# pmg1s3 register map
Vendor: Infineon Technologies; Series: PMG1S3; File version: 1.0
CPU: CM0PLUS r0p1, little endian, MPU, no FPU, VTOR, 2 interrupt priority bits, 32 interrupts
Registers are 32-bit, read-write, reset 0x0 unless marked. A register's access mark holds for its fields unless they carry their own. Offsets are from the block's base; [hi:lo] are bit positions; lines under a group give offsets from that group; {n}, {i} and the like mark numbered series; 'fields as' and 'values as' point back to an identical list; <NAME> marks a mode.

## USBFS — USB Device Controller
Base 0x402C0000
{0x0+4i} EP0_DR[{i}] (i=0..7) — Control End point EP0 Data Register
  [7:0] DATA_BYTE — This register is shared for both transmit and receive. The count in the EP0_CNT register determines the number of bytes received or to be transferred.
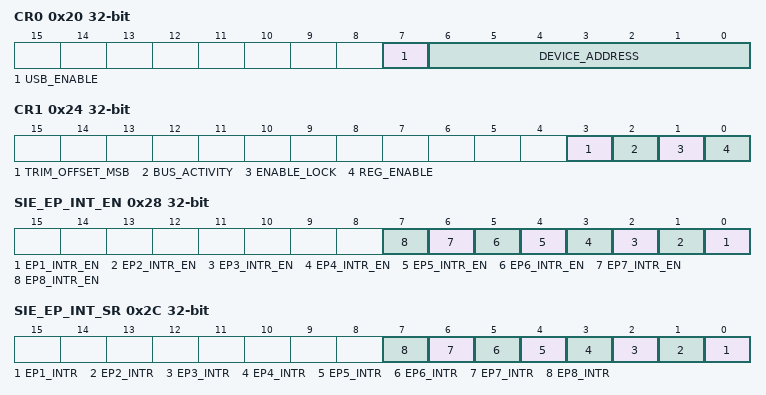
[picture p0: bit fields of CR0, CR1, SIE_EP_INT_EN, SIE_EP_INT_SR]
0x20 CR0 — USB control 0 Register
  [7] USB_ENABLE — This bit enables the device to respond to USB traffic.
  [6:0] DEVICE_ADDRESS — These bits specify the USB device address to which the SIE will respond. This address must be set by firmware and is specified by the USB Host with a SET ADDRESS command during USB enumeration. This value must be programmed by firmware when assigned during enumeration. It is not set automatically by the hardware.
0x24 CR1 — USB control 1 Register
  [3] TRIM_OFFSET_MSB — This bit enables trim bit[7].
  [2] BUS_ACTIVITY write-0-clears — The Bus Activity bit is a stickybit that detects any non-idle USB event that has occurred on the USB bus. Once set to High by the SIE to indicate the bus activity this bit retains its logical High value until firmware clears it.
  [1] ENABLE_LOCK — This bit is set to turn on the automatic frequency locking of the internal oscillator to USB traffic. Unless an external clock is being provided this bit should remain set for proper USB operation.
  [0] REG_ENABLE — This bit controls the operation of the internal USB regulator. For applications with supply voltages in the 5V range this bit is set high to enable the internal regulator. For device supply voltage in the 3.3V range this bit is cleared to connect the transceiver directly to the supply.
0x28 SIE_EP_INT_EN — USB SIE Data Endpoints Interrupt Enable Register
  [n-1] EP{n}_INTR_EN (n=1..8) — Enables interrupt for EP{n}
0x2C SIE_EP_INT_SR — USB SIE Data Endpoint Interrupt Status
  [n-1] EP{n}_INTR write-1-clears (n=1..8) — Interrupt status for EP{n}
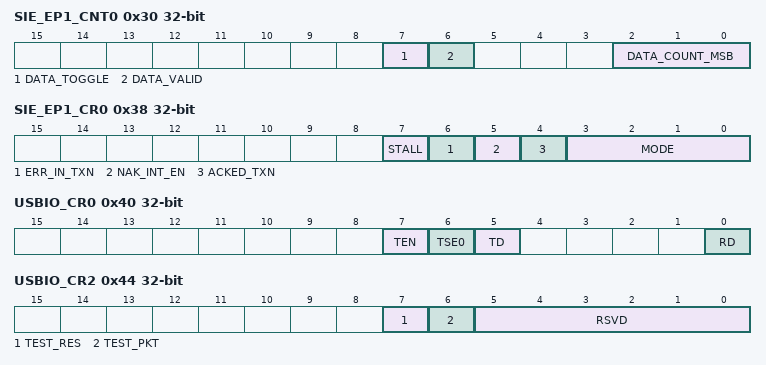
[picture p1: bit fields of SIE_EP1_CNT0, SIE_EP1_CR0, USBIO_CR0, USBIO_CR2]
0x30 SIE_EP1_CNT0 — Non-control endpoint count register
  [7] DATA_TOGGLE — This bit selects the DATA packet's toggle state. For IN transactions firmware must set this bit to the expected state. For OUT transactions the hardware sets this bit to the state of the received Data Toggle bit.
  [6] DATA_VALID write-0-clears — This bit is used for OUT transactions only and is read only. It is cleared to '0' if CRC bit stuffing errors or PID errors occur. This bit does not update for some endpoint mode settings.
    0=DATA_ERROR (No ACK'd transactions since bit was last cleared.); 1=DATA_VALID (Indicates a transaction ended with an ACK.)
  [2:0] DATA_COUNT_MSB — These bits are the 3 MSb bits of an 11-bit counter. The LSb are the Data Count[7:0] bits of the CNT1 register. Refer to the CNT1 register for more information.
0x34 SIE_EP1_CNT1 — Non-control endpoint count register
  [7:0] DATA_COUNT — These bits are the 8 LSb of a 11-bit counter. The 3 MSb bits are in the CNT0 register. The 11-bit count indicates the number of data bytes in a transaction.
0x38 SIE_EP1_CR0 — Non-control endpoint's control Register
  [7] STALL — When this bit is set the SIE stalls an OUT packet if the Mode bits are set to ACK-OUT. The SIE stalls an IN packet if the mode bits are set to ACK-IN. This bit must be clear for all other modes.
  [6] ERR_IN_TXN write-1-clears — The Error in transaction bit is set whenever an error is detected. For an IN transaction, this indicates a no response from HOST scenario. For an OUT transaction, this represents an RxErr (PID error/ CRC error/ bit-stuff error scenario). This bit is cleared by any writes to the register.
  [5] NAK_INT_EN — When set this bit causes an endpoint interrupt to be generated even when a transfer completes with a NAK.
  [4] ACKED_TXN write-1-clears — The ACK'd transaction bit is set whenever the SIE engages in a transaction to the register's endpoint that completes with an ACK packet. This bit is cleared by any writes to the register.
    0=ACKED_NO (No ACK'd transactions since bit was last cleared.); 1=ACKED_YES (Indicates a transaction ended with an ACK.)
  [3:0] MODE — The mode controls how the USB SIE responds to traffic and how the USB SIE changes the mode of that endpoint as a result of host packets to the endpoint.
    0=DISABLE (Ignore all USB traffic to this endpoint); 1=NAK_INOUT (SETUP: Accept IN: NAK OUT: NAK); 2=STATUS_OUT_ONLY (SETUP: Accept IN: STALL OUT: ACK 0B tokens, NAK others); 3=STALL_INOUT (SETUP: Accept IN: STALL OUT: STALL); 5=ISO_OUT (SETUP: Ignore IN: Ignore OUT: Accept Isochronous OUT token); 6=STATUS_IN_ONLY (SETUP: Accept IN: Respond with 0B data OUT: Stall); 7=ISO_IN (SETUP: Ignore IN: Accept Isochronous IN token OUT: Ignore); 8=NAK_OUT (SETUP: Ignore IN: Ignore OUT: NAK); 9=ACK_OUT (SETUP: Ignore IN: Ignore OUT: Accept data and ACK if STALL=0, STALL otherwise. ...); 11=ACK_OUT_STATUS_IN (SETUP: Accept IN: Respond with 0B data OUT: Accept data); 12=NAK_IN (SETUP: Ignore IN: NAK OUT: Ignore); 13=ACK_IN (SETUP: Ignore IN: Respond to IN with data if STALL=0, STALL otherwise OUT: Ignore); 15=ACK_INSTATUSOUT (SETUP: Accept IN: Respond to IN with data OUT: ACK 0B tokens, NAK others)
0x40 USBIO_CR0 (reset mask 0xE0) — USBIO Control 0 Register
  [7] TEN — USB Transmit Enable. This is used to manually transmit on the D+ and D- pins. Normally this bit should be cleared to allow the internal SIE to drive the pins. The most common reason for manually transmitting is to force a resume state on the bus.
  [6] TSE0 — Transmit Single-Ended Zero. SE0: both D+ and D- low. No effect if TEN=0.
  [5] TD — Transmit Data. Transmit a USB J or K state on the USB bus. No effect if TEN=0 or TSE0=1.
    0=DIFF_K (Force USB K state (D+ is low D- is high).); 1=DIFF_J (Force USB J state (D+ is high D- is low).)
  [0] RD ro — Received Data. This read only bit gives the state of the USB differential receiver.
    0=DIFF_LOW (D+ < D- (K state), or D+=D-=0 (SE0)); 1=DIFF_HIGH (D+ > D- (J state))
0x44 USBIO_CR2 — USBIO control 2 Register
  [7] TEST_RES — This bit is for testing the non-passthrough suspend mode pull up. When set, the resistor is applied to the D+ pin.
  [6] TEST_PKT — This bit enables the device to transmit a packet in response to an internally generated IN packet. When set, one packet will be generated.
  [5:0] RSVD ro
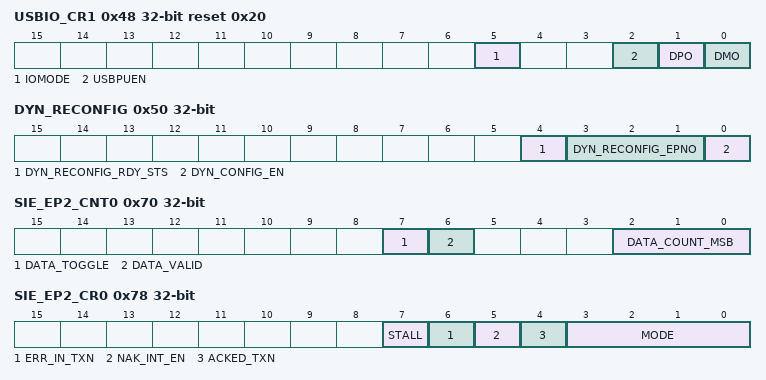
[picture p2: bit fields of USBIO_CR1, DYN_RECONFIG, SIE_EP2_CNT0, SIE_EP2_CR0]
0x48 USBIO_CR1 reset 0x20 (reset mask 0x24) — USBIO control 1 Register
  [5] IOMODE — This bit allows the D+ and D- pins to be configured for either USB mode or bit-banged modes. If this bit is set the DMI and DPI bits are used to drive the D- and D+ pins.
  [2] USBPUEN — This bit enables the connection of the internal 1.5 k pull up resistor on the D+ pin.
  [1] DPO ro — This read only bit gives the state of the D+ pin.
  [0] DMO ro — This read only bit gives the state of the D- pin.
0x50 DYN_RECONFIG — USB Dynamic reconfiguration register
  [4] DYN_RECONFIG_RDY_STS ro — This bit indicates the ready status for the dynamic reconfiguration, when set to 1, indicates the block is ready for reconfiguration.
  [3:1] DYN_RECONFIG_EPNO — These bits indicates the EP number for which reconfiguration is required when dyn_config_en bit is set to 1.
  [0] DYN_CONFIG_EN — This bit is used to enable the dynamic re-configuration for the selected EP. If set to 1, indicates the reconfiguration required for selected EP. Use 0 for EP1, 1 for EP2, etc.
0x60 SOF0 ro — Start Of Frame Register
  [7:0] FRAME_NUMBER — It has the lower 8 bits [7:0] of the SOF frame number.
0x64 SOF1 ro — Start Of Frame Register
  [2:0] FRAME_NUMBER_MSB — It has the upper 3 bits [10:8] of the SOF frame number.
0x70 SIE_EP2_CNT0 — Non-control endpoint count register
  fields as SIE_EP1_CNT0
0x74 SIE_EP2_CNT1 — Non-control endpoint count register
  fields as SIE_EP1_CNT1
0x78 SIE_EP2_CR0 — Non-control endpoint's control Register
  fields as SIE_EP1_CR0
0x80 OSCLK_DR0 ro reset not defined — Oscillator lock data register 0
  [7:0] ADDER — These bits return the lower 8 bits of the oscillator locking circuits adder output.
0x84 OSCLK_DR1 ro reset not defined — Oscillator lock data register 1
  [6:0] ADDER_MSB — These bits return the upper 7 bits of the oscillator locking circuits adder output.
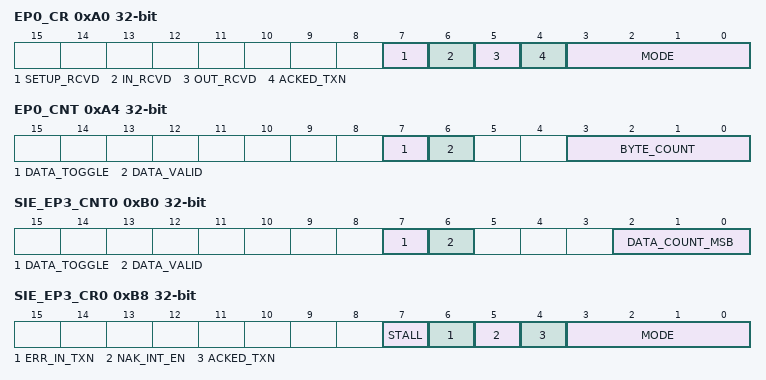
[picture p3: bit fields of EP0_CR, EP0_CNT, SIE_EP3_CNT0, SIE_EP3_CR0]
0xA0 EP0_CR — Endpoint0 control Register
  [7] SETUP_RCVD write-1-clears — When set this bit indicates a valid SETUP packet was received and ACKed. This bit is forced HIGH from the start of the data packet phase of the SETUP transaction until the start of the ACK packet returned by the SIE. The CPU is prevented from clearing this bit during this interval. After this interval the bit will remain set until cleared by firmware. While this bit is set to '1' the CPU cannot write to the EP0_DRx registers. This prevents firmware from overwriting an incoming SETUP transaction before firmware has a chance to read the SETUP data. This bit is cleared by any non-locked writes to the register.
  [6] IN_RCVD write-1-clears — When set this bit indicates a valid IN packet has been received. This bit is updated to '1' after the host acknowledges an IN data packet. When clear this bit indicates either no IN has been received or that the host did not acknowledge the IN data by sending ACK handshake. It is cleared by any writes to the register.
  [5] OUT_RCVD write-1-clears — When set this bit indicates a valid OUT packet has been received and ACKed. This bit is updated to '1' after the last received packet in an OUT transaction. When clear this bit indicates no OUT received. It is cleared by any writes to the register.
  [4] ACKED_TXN write-1-clears — The ACK'd transaction bit is set whenever the SIE engages in a transaction to the register's endpoint that completes with an ACK packet. This bit is cleared by any writes to the register.
    values as SIE_EP1_CR0.ACKED_TXN
  [3:0] MODE — The mode controls how the USB SIE responds to traffic and how the USB SIE changes the mode of that endpoint as a result of host packets to the endpoint.
    values as SIE_EP1_CR0.MODE
0xA4 EP0_CNT — Endpoint0 count Register
  [7] DATA_TOGGLE — This bit selects the DATA packet's toggle state. For IN transactions firmware must set this bit to the expected state. For OUT transactions the hardware sets this bit to the state of the received Data Toggle bit.
  [6] DATA_VALID write-0-clears — This bit is used for OUT/SETUP transactions only and is read only. It is cleared to '0' if CRC bit stuffing errors or PID errors occur. This bit does not update for some endpoint mode settings.
    values as SIE_EP1_CNT0.DATA_VALID
  [3:0] BYTE_COUNT — These bits indicate the number of data bytes in a transaction. For IN transactions firmware loads the count with the number of bytes to be transmitted to the host from the endpoint FIFO. Valid values are 0 to 8. For OUT or SETUP transactions the count is updated by hardware to the number of data bytes received plus two for the CRC bytes. Valid values are 2 to 10.
0xB0 SIE_EP3_CNT0 — Non-control endpoint count register
  fields as SIE_EP1_CNT0
0xB4 SIE_EP3_CNT1 — Non-control endpoint count register
  fields as SIE_EP1_CNT1
0xB8 SIE_EP3_CR0 — Non-control endpoint's control Register
  fields as SIE_EP1_CR0
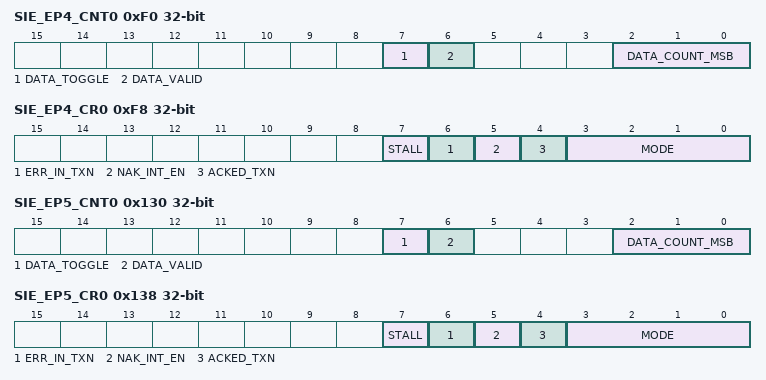
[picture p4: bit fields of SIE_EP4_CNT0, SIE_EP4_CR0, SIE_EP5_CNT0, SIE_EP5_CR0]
0xF0 SIE_EP4_CNT0 — Non-control endpoint count register
  fields as SIE_EP1_CNT0
0xF4 SIE_EP4_CNT1 — Non-control endpoint count register
  fields as SIE_EP1_CNT1
0xF8 SIE_EP4_CR0 — Non-control endpoint's control Register
  fields as SIE_EP1_CR0
0x130 SIE_EP5_CNT0 — Non-control endpoint count register
  fields as SIE_EP1_CNT0
0x134 SIE_EP5_CNT1 — Non-control endpoint count register
  fields as SIE_EP1_CNT1
0x138 SIE_EP5_CR0 — Non-control endpoint's control Register
  fields as SIE_EP1_CR0
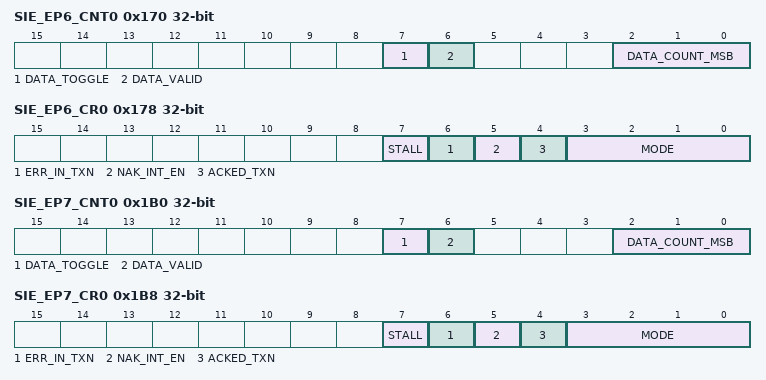
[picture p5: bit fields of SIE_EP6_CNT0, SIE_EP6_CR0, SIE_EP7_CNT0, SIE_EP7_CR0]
0x170 SIE_EP6_CNT0 — Non-control endpoint count register
  fields as SIE_EP1_CNT0
0x174 SIE_EP6_CNT1 — Non-control endpoint count register
  fields as SIE_EP1_CNT1
0x178 SIE_EP6_CR0 — Non-control endpoint's control Register
  fields as SIE_EP1_CR0
0x1B0 SIE_EP7_CNT0 — Non-control endpoint count register
  fields as SIE_EP1_CNT0
0x1B4 SIE_EP7_CNT1 — Non-control endpoint count register
  fields as SIE_EP1_CNT1
0x1B8 SIE_EP7_CR0 — Non-control endpoint's control Register
  fields as SIE_EP1_CR0
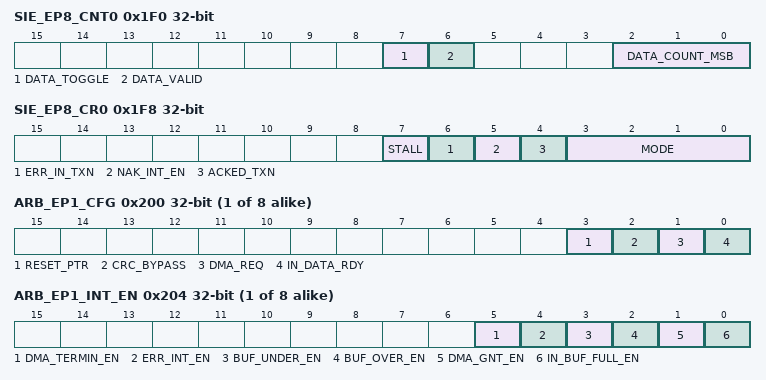
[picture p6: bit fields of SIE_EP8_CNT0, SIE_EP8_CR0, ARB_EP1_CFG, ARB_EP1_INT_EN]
0x1F0 SIE_EP8_CNT0 — Non-control endpoint count register
  fields as SIE_EP1_CNT0
0x1F4 SIE_EP8_CNT1 — Non-control endpoint count register
  fields as SIE_EP1_CNT1
0x1F8 SIE_EP8_CR0 — Non-control endpoint's control Register
  fields as SIE_EP1_CR0
{0x1C0+0x40*i} ARB_EP{i}_CFG (i=1..8) — Endpoint Configuration Register
  [3] RESET_PTR — Configuration Setting to Reset the RA and WA Pointers to their start values at the End of Packet transaction.
    0=RESET_KRYPTON (Do not Reset Pointer; Krypton Backward compatibility mode); 1=RESET_NORMAL (Reset Pointer; recommended value for reduction of CPU Configuration Writes.)
  [2] CRC_BYPASS — Configuration Setting to prevent CRC bytes from being written to memory and being read by firmware
    0=CRC_NORMAL (No CRC bypass; CRC bytes will be written to memory and Termin will be generated for the CRC byte/s); 1=CRC_BYPASS (CRC Bypass Set; CRC bytes will not be written into memory and Termin will be generated for the last data byte/s)
  [1] DMA_REQ — Manual DMA Request for a particular (1 to 8) endpoint; changing this field from 0 to 1 causes a DMA request to be generated.
  [0] IN_DATA_RDY — Indication that Endpoint Packet Data is Ready in Main memory
{0x1C4+0x40*i} ARB_EP{i}_INT_EN (i=1..8) — Endpoint Interrupt Enable Register
  [5] DMA_TERMIN_EN — Endpoint DMA Terminated Enable
  [4] ERR_INT_EN — Endpoint Error in Transaction Interrupt Enable
  [3] BUF_UNDER_EN — Endpoint Buffer Underflow Enable
  [2] BUF_OVER_EN — Endpoint Buffer Overflow Enable
  [1] DMA_GNT_EN — Endpoint DMA Grant Enable
  [0] IN_BUF_FULL_EN — IN Endpoint Local Buffer Full Enable
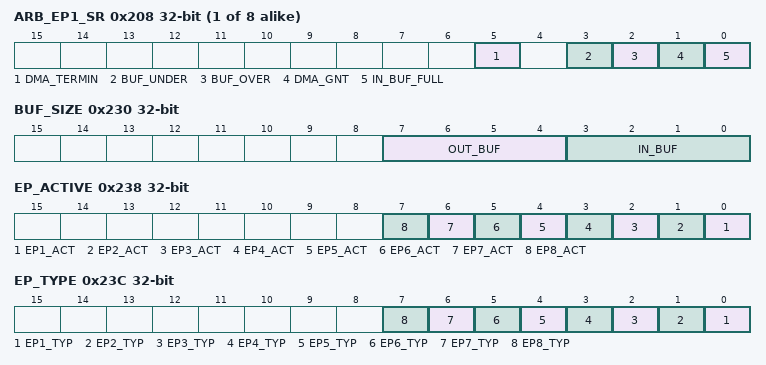
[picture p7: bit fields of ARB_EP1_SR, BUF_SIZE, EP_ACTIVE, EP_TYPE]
{0x1C8+0x40*i} ARB_EP{i}_SR (i=1..8) — Endpoint Interrupt Enable Register
  [5] DMA_TERMIN write-1-clears — Endpoint DMA Terminated Interrupt
  [3] BUF_UNDER write-1-clears — Endpoint Buffer Underflow Interrupt
  [2] BUF_OVER write-1-clears — Endpoint Buffer Overflow Interrupt
  [1] DMA_GNT write-1-clears — Endpoint DMA Grant Interrupt
  [0] IN_BUF_FULL write-1-clears — IN Endpoint Local Buffer Full Interrupt
{0x1D0+0x40*i} ARB_RW{i}_WA (i=1..8) — Endpoint Write Address value
  [7:0] WA — Write Address for EP
{0x1D4+0x40*i} ARB_RW{i}_WA_MSB (i=1..8) — Endpoint Write Address value
  [0] WA_MSB — Write Address for EP
{0x1D8+0x40*i} ARB_RW{i}_RA (i=1..8) — Endpoint Read Address value
  [7:0] RA — Read Address for EP
{0x1DC+0x40*i} ARB_RW{i}_RA_MSB (i=1..8) — Endpoint Read Address value
  [0] RA_MSB — Read Address for EP
{0x1E0+0x40*i} ARB_RW{i}_DR reset not defined (i=1..8) — Endpoint Data Register
  [7:0] DR — Data Register for EP ; This register is linked to the memory, hence reset value is undefined
0x230 BUF_SIZE — Dedicated Endpoint Buffer Size Register
  [7:4] OUT_BUF — Buffer size for OUT Endpoints.
  [3:0] IN_BUF — Buffer size for IN Endpoints.
0x238 EP_ACTIVE — Endpoint Active Indication Register
  [n-1] EP{n}_ACT (n=1..8) — Indicates that Endpoint is currently active.
0x23C EP_TYPE — Endpoint Type (IN/OUT) Indication
  [all] fields
    0=EP_IN (IN outpoint); 1=EP_OUT (OUT outpoint)
  [n-1] EP{n}_TYP (n=1..8) — Endpoint Type Indication.
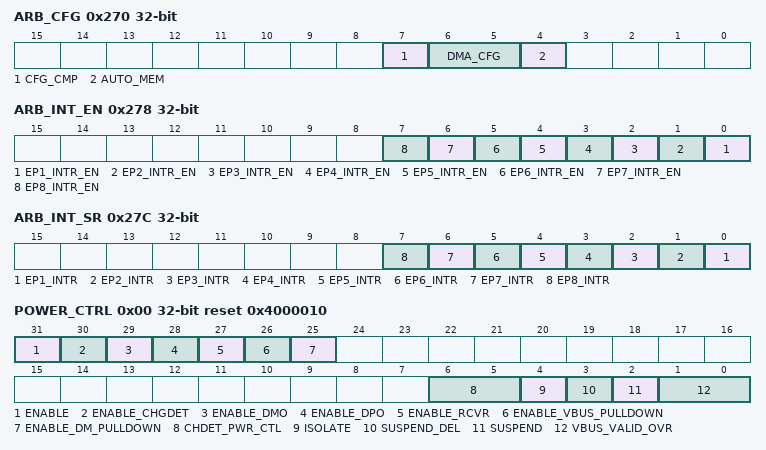
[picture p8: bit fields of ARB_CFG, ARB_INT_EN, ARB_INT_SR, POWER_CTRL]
0x270 ARB_CFG — Arbiter Configuration Register
  [7] CFG_CMP — Register Configuration Complete Indication. Posedge is detected on this bit. Hence a 0 to 1 transition is required.
  [6:5] DMA_CFG — DMA Access Configuration.
    0=DMA_NONE (No DMA); 1=DMA_MANUAL (Manual DMA); 2=DMA_AUTO (Auto DMA)
  [4] AUTO_MEM — Enables Auto Memory Configuration. Manual memory configuration by default.
0x274 USB_CLK_EN — USB Block Clock Enable Register
  [0] CSR_CLK_EN — Clock Enable for Core Logic clocked by AHB bus clock
0x278 ARB_INT_EN — Arbiter Interrupt Enable
  [n-1] EP{n}_INTR_EN (n=1..8) — Enables interrupt for EP{n}
0x27C ARB_INT_SR ro — Arbiter Interrupt Status
  [n-1] EP{n}_INTR (n=1..8) — Interrupt status for EP{n}
0x2B0 CWA — Common Area Write Address
  [7:0] CWA — Write Address for Common Area
0x2B4 CWA_MSB — Endpoint Read Address value
  [0] CWA_MSB — Write Address for Common Area
0x2F0 DMA_THRES — DMA Burst / Threshold Configuration
  [7:0] DMA_THS — DMA Threshold count
0x2F4 DMA_THRES_MSB — DMA Burst / Threshold Configuration
  [0] DMA_THS_MSB — DMA Threshold count
0x330 BUS_RST_CNT reset 0xA — Bus Reset Count Register
  [3:0] BUS_RST_CNT — Bus Reset Count Length
{0x400+4i} MEM_DATA[{i}] (i=0..511) reset not defined — DATA
  fields as ARB_RW1_DR
0x1060 SOF16 ro — Start Of Frame Register
  [10:0] FRAME_NUMBER16 — The frame number (11b)
0x1080 OSCLK_DR16 ro reset not defined — Oscillator lock data register
  [14:0] ADDER16 — These bits return the oscillator locking circuits adder output.
{0x11D0+0x40*i} ARB_RW{i}_WA16 (i=1..8) — Endpoint Write Address value
  [8:0] WA16 — Write Address for EP
{0x11D8+0x40*i} ARB_RW{i}_RA16 (i=1..8) — Endpoint Read Address value
  [8:0] RA16 — Read Address for EP
{0x11E0+0x40*i} ARB_RW{i}_DR16 reset not defined (i=1..8) — Endpoint Data Register
  [15:0] DR16 — Data Register for EP ; This register is linked to the memory, hence reset value is undefined
0x12B0 CWA16 — Common Area Write Address
  [8:0] CWA16 — Write Address for Common Area
0x12F0 DMA_THRES16 — DMA Burst / Threshold Configuration
  [8:0] DMA_THS16 — DMA Threshold count
0x2000 BCD group — USB Device Controller Battery Charger Detect
  0x00 POWER_CTRL reset 0x4000010 — Power Control Register
    [31] ENABLE — Mast enable of PHY and Charger Detector. Nothing will work until this bit is set.
    [30] ENABLE_CHGDET — Enables the charger detection circuitry. After USB has connected, this circuitry can be disabled to save power.
    [29] ENABLE_DMO — Enables the signle ended receiver on D-.
    [28] ENABLE_DPO — Enables the single ended receiver on D+.
    [27] ENABLE_RCVR — Enables the differential USB receiver.
    [26] ENABLE_VBUS_PULLDOWN — Enables the weak pull down on the VBUS, default on, to prevent floating node crow bar currents.
    [25] ENABLE_DM_PULLDOWN — Enables the ~15k pull down on the DM, default off. The 15k pull down is needed for Data Contact Detection (DCD).
    [6:5] CHDET_PWR_CTL — Power programmability for bandgap voltage buffer in the charger detect block. See s8bg_vrefbuf public cell for more information. Default '0' is low power mode.
    [4] ISOLATE — Isolates the PHY outputs. Clear this bit at least 2us after vbus is known to be valid (vbus_valid=1). Isolation will be forced when vbus_valid goes low (see VBUS_VALID_OVR).
    [3] SUSPEND_DEL — Delayed version of SUSPEND. Always set SUSPEND and SUSPEND_DEL together in a single register write. When taking PHY out of suspend mode, first clear SUSPEND, then clear SUSPEND_DEL at least 2us later.
    [2] SUSPEND — Put PHY into Suspend mode. If the PHY is enabled, this bit MUST be set before entering a low power mode (DeepSleep/Hibernate).
    [1:0] VBUS_VALID_OVR — Overrides the value received from the GPIO input buffer connected to VBUS: 0: Force vbus_valid=0 1: Force vbus_valid=1 2: Use vbus_valid signal from GPIO input 3: Use vbus_valid signal from PHY detector
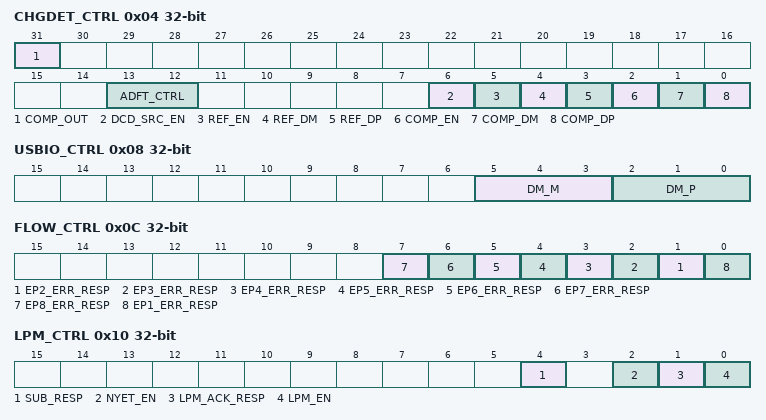
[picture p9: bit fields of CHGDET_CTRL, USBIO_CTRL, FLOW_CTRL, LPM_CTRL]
  0x04 CHGDET_CTRL (reset mask 0x307F) — Charger Detection Control Register
    [31] COMP_OUT ro — Output of the primary/secondary detection comparator. This output is not filtered or debounced and must be polled in software.
    [13:12] ADFT_CTRL — ADFT option to bring out buffered version of voltage reference input or adft intput to ADFT output (adft_out).
      0=ADFT_NORMAL (Normal operating mode, reference buffer used to generate internal references. adft_out pulled low.); 1=ADFT_VBG (Use reference buffer to bring out voltage reference input (vbg) onto adft_out.); 2=ADFT_DONTUSE (Illegal - do not use.); 3=ADFT_ADFTIN (Use reference buffer to bring out buffered version of system level adft input (adft_in) onto adft_out.)
    [6] DCD_SRC_EN — Enable the Data Contact Detect current source on D+
    [5] REF_EN — Enable the primary/secondary reference driver. This bit can be written concurrently with REF_DP/REF_DM.
    [4] REF_DM — Connect the primary/secondary detection reference driver to D-
    [3] REF_DP — Connect the primary/secondary detection reference driver to D+
    [2] COMP_EN — Enable the primary/secondary detection comparator and current sink. This bit can be written concurrently with COMP_DP/COMP_DM. Note that REF_EN must also be 1 for the comparator to work (because it receives a reference from it).
    [1] COMP_DM — Connect the primary/secondary detection comparator and current sink to D-
    [0] COMP_DP — Connect the primary/secondary detection comparator and current sink to D+
  0x08 USBIO_CTRL — USB IO Control Register
    [5:3] DM_M — The GPIO Drive Mode for DM IO pad.
    [2:0] DM_P — The GPIO Drive Mode for DP IO pad. This field only applies if USBIO_CR1.IOMODE =1. Data comes from the corresponding GPIO.DR register.
      0=OFF (Mode 0: Output buffer off (high Z). Input buffer off.); 1=INPUT (Mode 1: Output buffer off (high Z). Input buffer on.); 2=0_PU (Mode 2: Strong pull down ('0'), weak/resistive pull up (PU). Input buffer on.); 4=0_Z (Mode 4: Strong pull down ('0'), open drain (pull up off) ('1'). Input buffer on.); 6=Mode 6: Strong pull down ('0'), strong pull up ('1'). Input buffer on. Other values, not supported
  0x0C FLOW_CTRL — Flow Control Register
    [n-1] EP{n}_ERR_RESP (n=2..8) — End Point {n} error response
    [0] EP1_ERR_RESP — End Point 1 error response 0: do nothing (backward compatibility mode) 1: if this is an IN EP and an underflow occurs then cause a CRC error, if this is an OUT EP and an overflow occurs then send a NAK
  0x10 LPM_CTRL — LPM Control Register
    [4] SUB_RESP — Enable a STALL response for all undefined SubPIDs, i.e. other than LPM (0011b). If not enabled then there will be no response (Error) for the undefined SubPIDs.
    [2] NYET_EN — Allow firmware to choose which response to use for an LPM token (LPM_EN=1) when the device is NOT ready to go to the requested low power mode (LPM_ACK_RESP=0). 0: a LPM token will get an NAK response (indicating a CRC error), the host is expected to repeat the LPM token. 1: a LPM token will get a NYET response
    [1] LPM_ACK_RESP — LPM ACK response enable (if LPM_EN=1), to allow firmware to refuse a low power request 0: a LPM token will get a NYET or NAK (depending on NYET_EN bit below) response and the device will NOT go to a low power mode 1: a LPM token will get an ACK response and the device will go to the requested low power mode
    [0] LPM_EN — LPM enable 0: Disabled, LPM token will not get a response (backward compatibility mode) 1: Enable, LPM token will get a handshake response (ACK, STALL, NYET or NAK) A STALL will be sent if the bLinkState is not 0001b A NYET, NAK or ACK response will be sent depending on the NYET_EN and LPM_ACK_RESP bits below
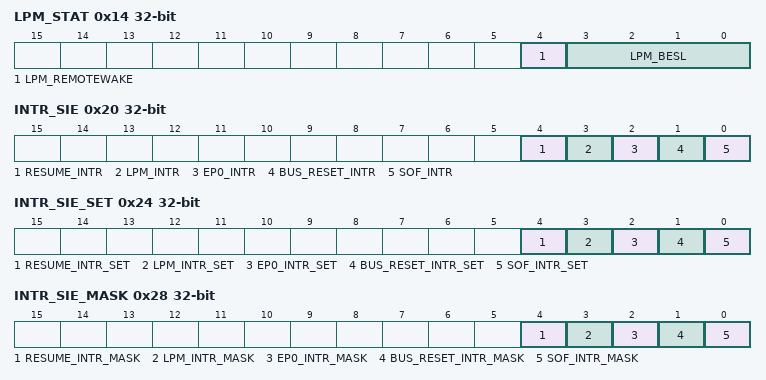
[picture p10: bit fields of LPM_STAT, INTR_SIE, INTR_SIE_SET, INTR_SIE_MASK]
  0x14 LPM_STAT ro — LPM Status register
    [4] LPM_REMOTEWAKE — 0: Device is prohibited from initiating a remote wake 1: Device is allow to wake the host
    [3:0] LPM_BESL — Best Effort Service Latency This value should match either the Baseline (DeepSleep) or Deep (Hibernate) BESL in the BOS descriptor.
  0x20 INTR_SIE — USB SOF, BUS RESET and EP0 Interrupt Status
    [4] RESUME_INTR write-1-clears — Interrupt status for Resume
    [3] LPM_INTR write-1-clears — Interrupt status for LPM (Link Power Management, L1 entry)
    [2] EP0_INTR write-1-clears — Interrupt status for EP0
    [1] BUS_RESET_INTR write-1-clears — Interrupt status for BUS RESET
    [0] SOF_INTR write-1-clears — Interrupt status for USB SOF
  0x24 INTR_SIE_SET — USB SOF, BUS RESET and EP0 Interrupt Set
    [4] RESUME_INTR_SET write-1-sets — Write with '1' to set corresponding bit in interrupt request register.
    [3] LPM_INTR_SET write-1-sets — Write with '1' to set corresponding bit in interrupt request register.
    [2] EP0_INTR_SET write-1-sets — Write with '1' to set corresponding bit in interrupt request register.
    [1] BUS_RESET_INTR_SET write-1-sets — Write with '1' to set corresponding bit in interrupt request register.
    [0] SOF_INTR_SET write-1-sets — Write with '1' to set corresponding bit in interrupt request register.
  0x28 INTR_SIE_MASK — USB SOF, BUS RESET and EP0 Interrupt Mask
    [4] RESUME_INTR_MASK — Set to 1 to enable interrupt corresponding to interrupt request register
    [3] LPM_INTR_MASK — Set to 1 to enable interrupt corresponding to interrupt request register
    [2] EP0_INTR_MASK — Set to 1 to enable interrupt corresponding to interrupt request register
    [1] BUS_RESET_INTR_MASK — Set to 1 to enable interrupt corresponding to interrupt request register
    [0] SOF_INTR_MASK — Set to 1 to enable interrupt corresponding to interrupt request register
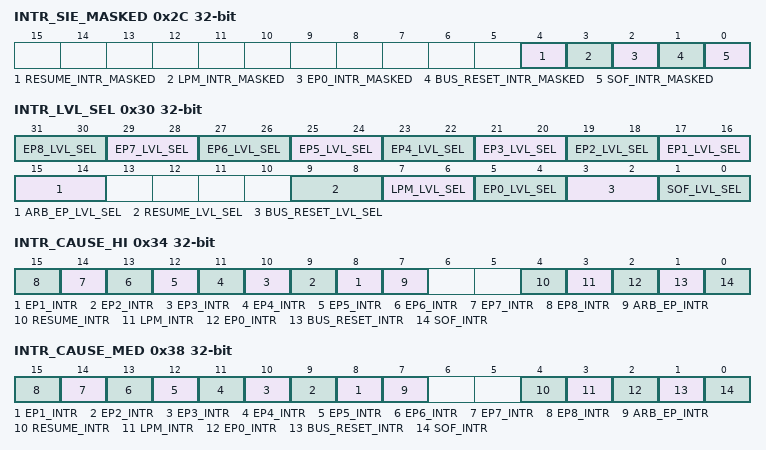
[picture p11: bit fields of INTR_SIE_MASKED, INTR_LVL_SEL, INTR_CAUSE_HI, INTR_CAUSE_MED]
  0x2C INTR_SIE_MASKED ro — USB SOF, BUS RESET and EP0 Interrupt Masked
    [4] RESUME_INTR_MASKED — Logical and of corresponding request and mask bits.
    [3] LPM_INTR_MASKED — Logical and of corresponding request and mask bits.
    [2] EP0_INTR_MASKED — Logical and of corresponding request and mask bits.
    [1] BUS_RESET_INTR_MASKED — Logical and of corresponding request and mask bits.
    [0] SOF_INTR_MASKED — Logical and of corresponding request and mask bits.
  0x30 INTR_LVL_SEL — Select interrupt level for each interrupt source
    [2n+15:2n+14] EP{n}_LVL_SEL (n=1..8) — EP{n} Interrupt level select
    [15:14] ARB_EP_LVL_SEL — Arbiter Endpoint Interrupt level select
    [9:8] RESUME_LVL_SEL — Resume Interrupt level select
    [7:6] LPM_LVL_SEL — LPM Interrupt level select
    [5:4] EP0_LVL_SEL — EP0 Interrupt level select
    [3:2] BUS_RESET_LVL_SEL — BUS RESET Interrupt level select
    [1:0] SOF_LVL_SEL — USB SOF Interrupt level select
      0=HI (High priority interrupt); 1=MED (Medium priority interrupt); 2=LO (Low priority interrupt); 3=RSVD (illegal)
  0x34 INTR_CAUSE_HI ro — High priority interrupt Cause register
    [n+7] EP{n}_INTR (n=1..8) — EP{n} Interrupt
    [7] ARB_EP_INTR — Arbiter Endpoint Interrupt
    [4] RESUME_INTR — Resume Interrupt
    [3] LPM_INTR — LPM Interrupt
    [2] EP0_INTR — EP0 Interrupt
    [1] BUS_RESET_INTR — BUS RESET Interrupt
    [0] SOF_INTR — USB SOF Interrupt
  0x38 INTR_CAUSE_MED ro — Medium priority interrupt Cause register
    fields as BCD.INTR_CAUSE_HI
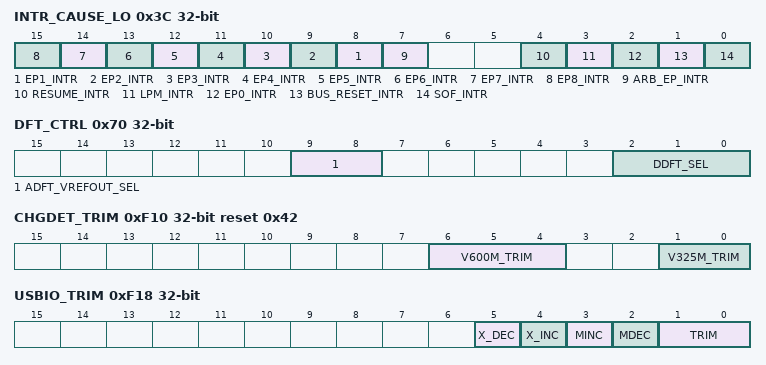
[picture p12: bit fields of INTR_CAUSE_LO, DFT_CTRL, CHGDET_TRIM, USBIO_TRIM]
  0x3C INTR_CAUSE_LO ro — Low priority interrupt Cause register
    fields as BCD.INTR_CAUSE_HI
  0x70 DFT_CTRL — DFT control
    [9:8] ADFT_VREFOUT_SEL — Select ADFT connection for VREF_OUT
      0=OPEN (no connections); 1=AMUXA (Connect adft_vref_out output to amuxbusa (should not be used because adft_vref_in connects to this bus)); 2=AMUXB (Connect adft_vref_out output to amuxbusb); 3=RSVD (N/A)
    [2:0] DDFT_SEL — DDFT select signal
      0=OFF (Nothing connected, output 0); 1=DP_SE (Single Ended output of DP); 2=DM_SE (Single Ended output of DM); 3=RCV_DF (Differential Receiver output); 4=CHRG_DET (Charger detect output); 5=VBUS_DET (Vbus detect output)
  0xF00 PHY_TRIM0 — PHY trim control register.
    [5:0] TRIM_DP_R_REG — Trim control for D+ pin poly termination resistors when PHY is in regulated mode. Default value is ~22Ohm. Increasing from 0 to 31 decreases the resistance to minimum. 32 gives the maximum resistance. Increasing from 32 to 62 decreases the resistance from maximum to default.
  0xF04 PHY_TRIM1 — PHY trim control register.
    [5:0] TRIM_DM_R_REG — Trim control for D- pin poly termination resistors when PHY is in regulated mode. Default value is ~22Ohm. Increasing from 0 to 31 decreases the resistance to minimum. 32 gives the maximum resistance. Increasing from 32 to 62 decreases the resistance from maximum to default.
  0xF08 PHY_TRIM2 — PHY trim control register.
    [5:0] TRIM_DP_R_BYPASS — Trim control for D+ pin poly termination resistors when PHY is in bypass mode. Default value is ~22Ohm. Increasing from 0 to 31 decreases the resistance to minimum. 32 gives the maximum resistance. Increasing from 32 to 62 decreases the resistance from maximum to default.
  0xF0C PHY_TRIM3 — PHY trim control register.
    [5:0] TRIM_DM_R_BYPASS — Trim control for D- pin poly termination resistors when PHY is in bypass mode. Default value is ~22Ohm. Increasing from 0 to 31 decreases the resistance to minimum. 32 gives the maximum resistance. Increasing from 32 to 62 decreases the resistance from maximum to default.
  0xF10 CHGDET_TRIM reset 0x42 — Charger detect trim values
    [6:4] V600M_TRIM — Trim bits for 600mV voltage reference. Used for charger detect voltage driver.
    [1:0] V325M_TRIM — Trim bits for 325mV voltage reference. Used for charger detect comparator reference.
  0xF14 TRIM — trim values
    [1:0] DM_PD_VAL — Trim bit for DM Pull Down register, to get resistance value close enough to 15kohm
  0xF18 USBIO_TRIM — trim values for IOs
    [5] X_DEC — This bit enables a decrease of the USB crossover voltage.
    [4] X_INC — This bit enables a increase of the USB crossover voltage.
    [3] MINC — When set this bit increases the USB edge matching ratio
    [2] MDEC — When set this bit decreases the USB edge matching ratio.
    [1:0] TRIM — These two bits of trim are for the suspend mode resistor.
      0=TRIM_NO (No effect.); 1=TRIM_LOWER (Lower idle voltage); 2=TRIM_HIGHER (Higher idle voltage); 3=TRIM_DONT_USE (Do not use)
